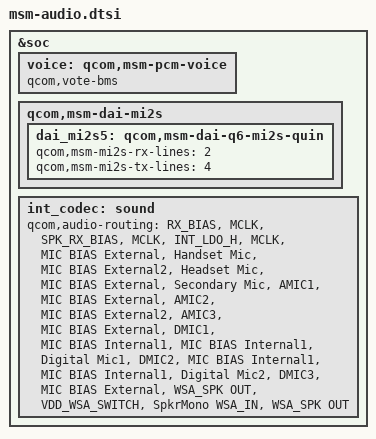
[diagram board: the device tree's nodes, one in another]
/*
 * Copyright (c) 2015-2016, The Linux Foundation. All rights reserved.
 *
 * This program is free software; you can redistribute it and/or modify
 * it under the terms of the GNU General Public License version 2 and
 * only version 2 as published by the Free Software Foundation.
 *
 * This program is distributed in the hope that it will be useful,
 * but WITHOUT ANY WARRANTY; without even the implied warranty of
 * MERCHANTABILITY or FITNESS FOR A PARTICULAR PURPOSE.  See the
 * GNU General Public License for more details.
 */

&soc {
	voice: qcom,msm-pcm-voice {
		qcom,vote-bms;
	};

	qcom,msm-dai-mi2s {
		dai_mi2s5: qcom,msm-dai-q6-mi2s-quin {
			qcom,msm-mi2s-rx-lines = <2>;
			qcom,msm-mi2s-tx-lines = <4>;
		};
	};

	int_codec: sound {
		qcom,audio-routing =
			"RX_BIAS", "MCLK",
			"SPK_RX_BIAS", "MCLK",
			"INT_LDO_H", "MCLK",
			"MIC BIAS External", "Handset Mic",
			"MIC BIAS External2", "Headset Mic",
			"MIC BIAS External", "Secondary Mic",
			"AMIC1", "MIC BIAS External",
			"AMIC2", "MIC BIAS External2",
			"AMIC3", "MIC BIAS External",
			"DMIC1", "MIC BIAS Internal1",
			"MIC BIAS Internal1", "Digital Mic1",
			"DMIC2", "MIC BIAS Internal1",
			"MIC BIAS Internal1", "Digital Mic2",
			"DMIC3", "MIC BIAS External",
			"WSA_SPK OUT", "VDD_WSA_SWITCH",
			"SpkrMono WSA_IN", "WSA_SPK OUT";

	};

};


